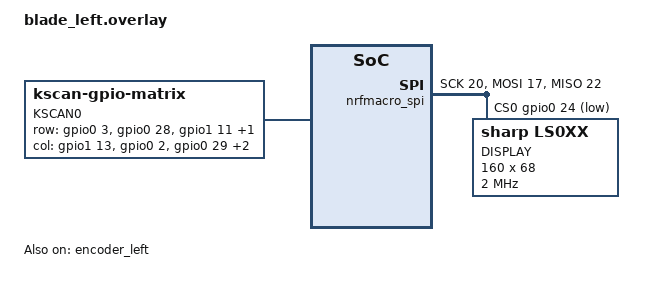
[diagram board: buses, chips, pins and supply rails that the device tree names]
/*
 * Copyright (c) 2020 The ZMK Contributors
 *
 * SPDX-License-Identifier: MIT
 */

#include "blade.dtsi"

/* Define kscan pins */
/ {
	kscan0: kscan0 {
		compatible = "zmk,kscan-gpio-matrix";
		label = "KSCAN0";

		diode-direction = "col2row";
		row-gpios
			= <&gpio0  3 (GPIO_ACTIVE_HIGH | GPIO_PULL_DOWN)>
			, <&gpio0 28 (GPIO_ACTIVE_HIGH | GPIO_PULL_DOWN)>
			, <&gpio1 11 (GPIO_ACTIVE_HIGH | GPIO_PULL_DOWN)>
			, <&gpio0 10 (GPIO_ACTIVE_HIGH | GPIO_PULL_DOWN)>
			;
   	col-gpios
      = <&gpio1 13 GPIO_ACTIVE_HIGH>
		  , <&gpio0  2 GPIO_ACTIVE_HIGH>
		  , <&gpio0 29 GPIO_ACTIVE_HIGH>
		  , <&gpio0 31 GPIO_ACTIVE_HIGH>
		  , <&gpio0 30 GPIO_ACTIVE_HIGH>
		  ;
	};
};

/* Voltage divider based fuel gauge */
&chosen {
		zmk,battery = &vbatt;
};

/* Define display */ 
&chosen {
  zephyr,display = &lcd;
};

&nrfmacro_spi {
  // activate this device
  status = "okay";

  compatible = "nordic,nrf-spim";
  sck-pin = <20>;
  mosi-pin = <17>;
  cs-gpios = <&gpio0 24 GPIO_ACTIVE_LOW>;
  // not used, but required by spim binding; can be reuesd in the keymap for normal key press
  miso-pin = <22>;


  // spi-device: gooddisplay GDEW0102T4
  // epd: il0323@0 {
  //   compatible = "gooddisplay,il0323";
  //   reg = <0>;
  //   label = "DISPLAY";
  //   spi-max-frequency = <4000000>;
  //   height = <128>;
  //   width = <80>;
  //   reset-gpios = <&gpio0 15  GPIO_ACTIVE_LOW>;
  //   dc-gpios    = <&gpio0 13  GPIO_ACTIVE_LOW>;
  //   busy-gpios  = <&gpio0  9  GPIO_ACTIVE_LOW>;
  //   pwr = [03 00 26 26];
  //   cdi = <0xd2>;
  //   tcon = <0x22>;
  // }; 
  
  lcd: ls0xx@0 {
		compatible = "sharp,ls0xx";
		label = "DISPLAY";
		spi-max-frequency = <2000000>;
		reg = <0>;
		width = <160>;
		height = <68>;
		// extcomin-gpios = <&pro_micro 2 GPIO_ACTIVE_HIGH>;
		// extcomin-frequency = <60>;
		// disp-en-gpios = <&pro_micro 3 GPIO_ACTIVE_HIGH>; 
	};
};

// Define encoder pins
&encoder_left {
	status = "okay";
  a-gpios = <&gpio1 4 (GPIO_ACTIVE_LOW | GPIO_PULL_UP)>;
	b-gpios = <&gpio1 6 (GPIO_ACTIVE_LOW | GPIO_PULL_UP)>;
};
